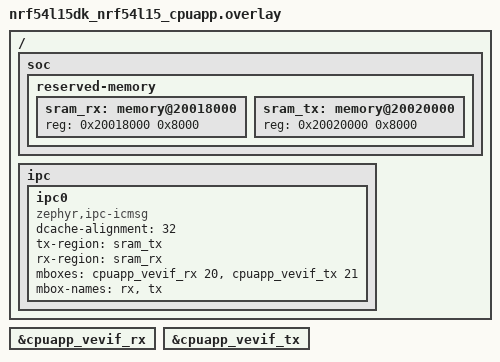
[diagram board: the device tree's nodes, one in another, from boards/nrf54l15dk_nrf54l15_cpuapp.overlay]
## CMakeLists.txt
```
#
# Copyright (c) 2024 Nordic Semiconductor ASA
#
# SPDX-License-Identifier: LicenseRef-Nordic-5-Clause
#

cmake_minimum_required(VERSION 3.20.0)

find_package(Zephyr REQUIRED HINTS $ENV{ZEPHYR_BASE})
project(ipc_service_host)

target_sources(app PRIVATE src/main.c)
```

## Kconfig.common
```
#
# Copyright (c) 2024 Nordic Semiconductor ASA
#
# SPDX-License-Identifier: LicenseRef-Nordic-5-Clause
#

config APP_IPC_SERVICE_SEND_INTERVAL
	int "Ipc service sending interval [us]"
	default 30 if BOARD_NRF5340DK_NRF5340_CPUNET
	default 70
	help
	  Time in micro seconds between sending subsequent data packages over
	  IPC service. Since kernel timeout has 1 ms resolution, the value is
	  rounded down. If value of this option is lower than 1000 us, busy
	  wait is used instead of sleep.

config APP_IPC_SERVICE_MESSAGE_LEN
	int "Length of single IPC message in bytes"
	default 100
```

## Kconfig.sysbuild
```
#
# Copyright (c) 2024 Nordic Semiconductor ASA
#
# SPDX-License-Identifier: LicenseRef-Nordic-5-Clause
#

source "share/sysbuild/Kconfig"

config REMOTE_BOARD
	string "The board used for remote target"
	default "nrf5340dk/nrf5340/cpunet" if BOARD_NRF5340DK_NRF5340_CPUAPP
	default "nrf5340dk/nrf5340/cpunet" if BOARD_NRF5340DK_NRF5340_CPUAPP_NS
	default "nrf54h20dk/nrf54h20/cpurad" if BOARD_NRF54H20DK_NRF54H20_CPUAPP
	default "nrf54l15dk/nrf54l15/cpuflpr" if BOARD_NRF54L15DK_NRF54L15_CPUAPP
	default "nrf54lm20pdk/nrf54lm20a/cpuflpr" if BOARD_NRF54LM20PDK_NRF54LM20A_CPUAPP
	default "nrf54lv10dk/nrf54lv10a/cpuflpr" if BOARD_NRF54LV10DK_NRF54LV10A_CPUAPP
```

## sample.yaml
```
sample:
  name: IPC Service integration test
  description: IPC Service integration and efficiency test

common:
  sysbuild: true
  tags:
    - ipc
    - ci_samples_ipc
  harness: console
  harness_config:
    type: multi_line
    ordered: true
    regex:
      - "IPC-service .* demo started"
      - "Δpkt: (?!0)\\d* ((?!0)\\d* B/pkt) | throughput: (?!0)\\d* bit/s"
      - "Δpkt: (?!0)\\d* ((?!0)\\d* B/pkt) | throughput: (?!0)\\d* bit/s"
      - "Δpkt: (?!0)\\d* ((?!0)\\d* B/pkt) | throughput: (?!0)\\d* bit/s"

tests:
  sample.ipc.ipc_service.nrf5340dk_rpmsg_default:
    platform_allow:
      - nrf5340dk/nrf5340/cpuapp
    integration_platforms:
      - nrf5340dk/nrf5340/cpuapp
  sample.ipc.ipc_service.nrf5340dk_rpmsg_cpuapp_sending:
    platform_allow:
      - nrf5340dk/nrf5340/cpuapp
    integration_platforms:
      - nrf5340dk/nrf5340/cpuapp
    extra_configs:
      - CONFIG_APP_IPC_SERVICE_SEND_INTERVAL=1
    extra_args:
      - remote_CONFIG_APP_IPC_SERVICE_SEND_INTERVAL=200000000
  sample.ipc.ipc_service.nrf5340dk_rpmsg_cpunet_sending:
    platform_allow:
      - nrf5340dk/nrf5340/cpuapp
    integration_platforms:
      - nrf5340dk/nrf5340/cpuapp
    extra_configs:
      - CONFIG_APP_IPC_SERVICE_SEND_INTERVAL=200000000
    extra_args:
      - remote_CONFIG_APP_IPC_SERVICE_SEND_INTERVAL=1
    harness_config:
      type: multi_line
      ordered: true
      regex:
        - "IPC-service .* demo started"
        # there will be only single tranfser from this core
        - "Δpkt: (?!0)\\d+ ((?!0)\\d+ B/pkt) | throughput: (?!0)\\d+ bit/s"
        - "Δpkt: \\d+ (\\d+ B/pkt) | throughput: \\d+ bit/s"
        - "Δpkt: \\d+ (\\d+ B/pkt) | throughput: \\d+ bit/s"
  sample.ipc.ipc_service.nrf5340dk_icmsg_default:
    platform_allow:
      - nrf5340dk/nrf5340/cpuapp
    integration_platforms:
      - nrf5340dk/nrf5340/cpuapp
    extra_args:
      - FILE_SUFFIX=icmsg
  sample.ipc.ipc_service.nrf5340dk_icbmsg_default:
    platform_allow:
      - nrf5340dk/nrf5340/cpuapp
    integration_platforms:
      - nrf5340dk/nrf5340/cpuapp
    extra_args:
      - FILE_SUFFIX=icbmsg
  sample.ipc.ipc_service.nrf5340dk_icmsg_cpuapp_sending:
    platform_allow:
      - nrf5340dk/nrf5340/cpuapp
    integration_platforms:
      - nrf5340dk/nrf5340/cpuapp
    extra_configs:
      - CONFIG_APP_IPC_SERVICE_SEND_INTERVAL=35
    extra_args:
      - FILE_SUFFIX=icmsg
      - remote_CONFIG_APP_IPC_SERVICE_SEND_INTERVAL=200000000
  sample.ipc.ipc_service.nrf5340dk_icmsg_cpunet_sending:
    platform_allow:
      - nrf5340dk/nrf5340/cpuapp
    integration_platforms:
      - nrf5340dk/nrf5340/cpuapp
    extra_configs:
      - CONFIG_APP_IPC_SERVICE_SEND_INTERVAL=200000000
    extra_args:
      - FILE_SUFFIX=icmsg
      - remote_CONFIG_APP_IPC_SERVICE_SEND_INTERVAL=1
    harness_config:
      type: multi_line
      ordered: true
      regex:
        - "IPC-service .* demo started"
        # there will be only single tranfser from this core
        - "Δpkt: (?!0)\\d+ ((?!0)\\d+ B/pkt) | throughput: (?!0)\\d+ bit/s"
        - "Δpkt: \\d+ (\\d+ B/pkt) | throughput: \\d+ bit/s"
        - "Δpkt: \\d+ (\\d+ B/pkt) | throughput: \\d+ bit/s"
  sample.ipc.ipc_service.nrf54h20dk_cpuapp_cpurad_icmsg:
    platform_allow:
      - nrf54h20dk/nrf54h20/cpuapp
    integration_platforms:
      - nrf54h20dk/nrf54h20/cpuapp
    extra_args:
      - ipc_service_CONFIG_SOC_NRF54H20_CPURAD_ENABLE=y
    timeout: 20
  sample.ipc.ipc_service.nrf54h20dk_cpuapp_cpuppr_icmsg:
    platform_allow:
      - nrf54h20dk/nrf54h20/cpuapp
    integration_platforms:
      - nrf54h20dk/nrf54h20/cpuapp
    extra_args:
      - FILE_SUFFIX=cpuppr
      - ipc_service_SNIPPET=nordic-ppr
    timeout: 20
  sample.ipc.ipc_service.nrf54l15dk_cpuapp_cpuflpr_icmsg:
    extra_args:
      - ipc_service_SNIPPET=nordic-flpr
    platform_allow:
      - nrf54l15dk/nrf54l15/cpuapp
    integration_platforms:
      - nrf54l15dk/nrf54l15/cpuapp
    timeout: 20
  sample.ipc.ipc_service.nrf54l15dk_cpuapp_cpuflpr_icbmsg:
    extra_args:
      - ipc_service_SNIPPET=nordic-flpr
      - ipc_service_CONFIG_IPC_SERVICE_BACKEND_ICBMSG_NUM_EP=1
      - ipc_service_DTC_OVERLAY_FILE="boards/nrf54l15dk_nrf54l15_cpuapp_icbmsg.overlay"
      - remote_CONFIG_IPC_SERVICE_BACKEND_ICBMSG_NUM_EP=1
      - remote_DTC_OVERLAY_FILE="boards/nrf54l15dk_nrf54l15_cpuflpr_icbmsg.overlay"
    platform_allow:
      - nrf54l15dk/nrf54l15/cpuapp
    integration_platforms:
      - nrf54l15dk/nrf54l15/cpuapp
    timeout: 20
  sample.ipc.ipc_service.nrf54lm20pdk_cpuapp_cpuflpr_icmsg:
    extra_args:
      - ipc_service_SNIPPET=nordic-flpr
    platform_allow:
      - nrf54lm20pdk/nrf54lm20a/cpuapp
      - nrf54lm20pdk@0.0.0/nrf54lm20a/cpuapp
      - nrf54lm20pdk@0.2.0/nrf54lm20a/cpuapp
      - nrf54lm20pdk@0.2.0.csp/nrf54lm20a/cpuapp
    integration_platforms:
      - nrf54lm20pdk/nrf54lm20a/cpuapp
    timeout: 20
  sample.ipc.ipc_service.nrf54lm20pdk_cpuapp_cpuflpr_icbmsg:
    extra_args:
      - ipc_service_SNIPPET=nordic-flpr
      - ipc_service_CONFIG_IPC_SERVICE_BACKEND_ICBMSG_NUM_EP=1
      - ipc_service_DTC_OVERLAY_FILE="boards/nrf54lm20pdk_nrf54lm20a_cpuapp_icbmsg.overlay"
      - remote_CONFIG_IPC_SERVICE_BACKEND_ICBMSG_NUM_EP=1
      - remote_DTC_OVERLAY_FILE="boards/nrf54lm20pdk_nrf54lm20a_cpuflpr_icbmsg.overlay"
    platform_allow:
      - nrf54lm20pdk/nrf54lm20a/cpuapp
      - nrf54lm20pdk@0.0.0/nrf54lm20a/cpuapp
      - nrf54lm20pdk@0.2.0/nrf54lm20a/cpuapp
      - nrf54lm20pdk@0.2.0.csp/nrf54lm20a/cpuapp
    integration_platforms:
      - nrf54lm20pdk/nrf54lm20a/cpuapp
    timeout: 20
  sample.ipc.ipc_service.nrf54lv10dk_cpuapp_cpuflpr_icmsg:
    extra_args:
      - ipc_service_SNIPPET=nordic-flpr
    platform_allow:
      - nrf54lv10dk/nrf54lv10a/cpuapp
      - nrf54lv10dk@0.0.0/nrf54lv10a/cpuapp
      - nrf54lv10dk@0.2.0/nrf54lv10a/cpuapp
    integration_platforms:
      - nrf54lv10dk/nrf54lv10a/cpuapp
    timeout: 20
  sample.ipc.ipc_service.nrf54lv10dk_cpuapp_cpuflpr_icbmsg:
    extra_args:
      - ipc_service_SNIPPET=nordic-flpr
      - ipc_service_CONFIG_IPC_SERVICE_BACKEND_ICBMSG_NUM_EP=1
      - ipc_service_DTC_OVERLAY_FILE="boards/nrf54lv10dk_nrf54lv10a_cpuapp_icbmsg.overlay"
      - remote_CONFIG_IPC_SERVICE_BACKEND_ICBMSG_NUM_EP=1
      - remote_DTC_OVERLAY_FILE="boards/nrf54lv10dk_nrf54lv10a_cpuflpr_icbmsg.overlay"
    platform_allow:
      - nrf54lv10dk/nrf54lv10a/cpuapp
      - nrf54lv10dk@0.0.0/nrf54lv10a/cpuapp
      - nrf54lv10dk@0.2.0/nrf54lv10a/cpuapp
    integration_platforms:
      - nrf54lv10dk/nrf54lv10a/cpuapp
    timeout: 20
```

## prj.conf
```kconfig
# Copyright (c) 2024 Nordic Semiconductor ASA
# SPDX-License-Identifier: LicenseRef-Nordic-5-Clause

CONFIG_PRINTK=y

CONFIG_LOG=y
CONFIG_LOG_PROCESS_THREAD_PRIORITY=-15
CONFIG_LOG_PROCESS_THREAD_CUSTOM_PRIORITY=y

CONFIG_HEAP_MEM_POOL_SIZE=4096

CONFIG_MBOX=y

CONFIG_IPC_SERVICE=y
CONFIG_IPC_SERVICE_LOG_LEVEL_INF=y
```

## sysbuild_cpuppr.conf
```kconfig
# Copyright (c) 2024 Nordic Semiconductor ASA
# SPDX-License-Identifier: LicenseRef-Nordic-5-Clause

SB_CONFIG_REMOTE_BOARD="nrf54h20dk/nrf54h20/cpuppr"
```

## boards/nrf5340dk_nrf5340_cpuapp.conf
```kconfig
#
# Copyright (c) 2022 Nordic Semiconductor ASA
#
# SPDX-License-Identifier: LicenseRef-Nordic-5-Clause
#

CONFIG_SOC_NRF53_CPUNET_ENABLE=y
CONFIG_OPENAMP=y
CONFIG_OPENAMP_SLAVE=n
```

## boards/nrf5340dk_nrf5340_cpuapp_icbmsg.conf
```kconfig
#
# Copyright (c) 2025 Nordic Semiconductor ASA
#
# SPDX-License-Identifier: LicenseRef-Nordic-5-Clause
#

CONFIG_SOC_NRF53_CPUNET_ENABLE=y
CONFIG_APP_IPC_SERVICE_SEND_INTERVAL=0
```

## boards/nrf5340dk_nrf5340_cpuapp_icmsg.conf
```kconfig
#
# Copyright (c) 2024 Nordic Semiconductor ASA
#
# SPDX-License-Identifier: LicenseRef-Nordic-5-Clause
#

CONFIG_SOC_NRF53_CPUNET_ENABLE=y
CONFIG_APP_IPC_SERVICE_SEND_INTERVAL=60
```

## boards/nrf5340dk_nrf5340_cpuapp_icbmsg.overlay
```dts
/*
 * Copyright (c) 2025 Nordic Semiconductor ASA
 *
 * SPDX-License-Identifier: LicenseRef-Nordic-5-Clause
 */

/delete-node/ &ipc0;

/ {
	chosen {
		/delete-property/ zephyr,ipc_shm;
		/delete-property/ zephyr,bt-hci;
	};

	reserved-memory {
		/delete-node/ memory@20070000;

		sram_tx: memory@20070000 {
			reg = <0x20070000 0x8000>;
		};

		sram_rx: memory@20078000 {
			reg = <0x20078000 0x8000>;
		};
	};

	ipc0: ipc0 {
		compatible = "zephyr,ipc-icbmsg";
		tx-region = <&sram_tx>;
		rx-region = <&sram_rx>;
		tx-blocks = <20>;
		rx-blocks = <20>;
		mboxes = <&mbox 0>, <&mbox 1>;
		mbox-names = "tx", "rx";
		status = "okay";
	};
};
```

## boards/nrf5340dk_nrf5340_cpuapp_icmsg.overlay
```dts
/*
* Copyright (c) 2022 Nordic Semiconductor ASA
*
* SPDX-License-Identifier: LicenseRef-Nordic-5-Clause
*/

/delete-node/ &ipc0;

/ {
	chosen {
		/delete-property/ zephyr,ipc_shm;
		/delete-property/ zephyr,bt-hci;
	};

	reserved-memory {
		/delete-node/ memory@20070000;

		sram_tx: memory@20070000 {
			reg = <0x20070000 0x8000>;
		};

		sram_rx: memory@20078000 {
			reg = <0x20078000 0x8000>;
		};
	};

	ipc0: ipc0 {
		compatible = "zephyr,ipc-icmsg";
		tx-region = <&sram_tx>;
		rx-region = <&sram_rx>;
		mboxes = <&mbox 0>, <&mbox 1>;
		mbox-names = "tx", "rx";
		status = "okay";
	};
};
```

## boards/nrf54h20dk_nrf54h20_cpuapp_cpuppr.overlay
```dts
/*
 * Copyright (c) 2024 Nordic Semiconductor ASA
 * SPDX-License-Identifier: LicenseRef-Nordic-5-Clause
 */

/* Replace default ipc0 instance */
/delete-node/ &ipc0;

ipc0: &cpuapp_cpuppr_ipc {
	status = "okay";
};

&cpuppr_vevif {
	status = "okay";
};

&cpuapp_bellboard {
	status = "okay";
};

/ {
	chosen {
		/delete-property/ zephyr,bt-hci;
	};
};
```

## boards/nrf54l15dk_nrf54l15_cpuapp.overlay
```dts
/*
 * Copyright (c) 2025 Nordic Semiconductor ASA
 *
 * SPDX-License-Identifier: LicenseRef-Nordic-5-Clause
 */

/ {
	soc {
		reserved-memory {
			#address-cells = <1>;
			#size-cells = <1>;

			sram_rx: memory@20018000 {
				reg = <0x20018000 0x8000>;
			};

			sram_tx: memory@20020000 {
				reg = <0x20020000 0x8000>;
			};
		};
	};

	ipc {
		ipc0: ipc0 {
			compatible = "zephyr,ipc-icmsg";
			dcache-alignment = <32>;
			tx-region = <&sram_tx>;
			rx-region = <&sram_rx>;
			mboxes = <&cpuapp_vevif_rx 20>, <&cpuapp_vevif_tx 21>;
			mbox-names = "rx", "tx";
			status = "okay";
		};
	};
};

&cpuapp_vevif_rx {
	status = "okay";
};

&cpuapp_vevif_tx {
	status = "okay";
};
```

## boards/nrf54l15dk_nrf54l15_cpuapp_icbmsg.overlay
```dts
/*
 * Copyright (c) 2025 Nordic Semiconductor ASA
 *
 * SPDX-License-Identifier: LicenseRef-Nordic-5-Clause
 */

/ {
	soc {
		reserved-memory {
			#address-cells = <1>;
			#size-cells = <1>;

			sram_rx: memory@20018000 {
				reg = <0x20018000 0x8000>;
			};

			sram_tx: memory@20020000 {
				reg = <0x20020000 0x8000>;
			};
		};
	};

	ipc {
		ipc0: ipc0 {
			compatible = "zephyr,ipc-icbmsg";
			dcache-alignment = <32>;
			tx-region = <&sram_tx>;
			rx-region = <&sram_rx>;
			tx-blocks = <16>;
			rx-blocks = <18>;
			mboxes = <&cpuapp_vevif_rx 20>, <&cpuapp_vevif_tx 21>;
			mbox-names = "rx", "tx";
			status = "okay";
		};
	};
};

&cpuapp_vevif_rx {
	status = "okay";
};

&cpuapp_vevif_tx {
	status = "okay";
};
```

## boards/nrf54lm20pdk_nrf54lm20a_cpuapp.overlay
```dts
/*
 * Copyright (c) 2025 Nordic Semiconductor ASA
 *
 * SPDX-License-Identifier: LicenseRef-Nordic-5-Clause
 */

/ {
	soc {
		reserved-memory {
			#address-cells = <1>;
			#size-cells = <1>;

			sram_rx: memory@20057c00 {
				reg = <0x20057c00 0x8000>;
			};

			sram_tx: memory@2005fc00 {
				reg = <0x2005fc00 0x8000>;
			};
		};
	};

	ipc {
		ipc0: ipc0 {
			compatible = "zephyr,ipc-icmsg";
			dcache-alignment = <32>;
			tx-region = <&sram_tx>;
			rx-region = <&sram_rx>;
			mboxes = <&cpuapp_vevif_rx 20>, <&cpuapp_vevif_tx 21>;
			mbox-names = "rx", "tx";
			status = "okay";
		};
	};
};

&cpuapp_vevif_rx {
	status = "okay";
};

&cpuapp_vevif_tx {
	status = "okay";
};
```

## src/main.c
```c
/*
 * Copyright (c) 2022 Nordic Semiconductor ASA
 *
 * SPDX-License-Identifier: LicenseRef-Nordic-5-Clause
 */

#include <zephyr/kernel.h>
#include <zephyr/device.h>
#include <string.h>

#include <zephyr/logging/log.h>

#include <zephyr/ipc/ipc_service.h>

#ifdef CONFIG_TEST_EXTRA_STACK_SIZE
#define STACKSIZE	(1024 + CONFIG_TEST_EXTRA_STACK_SIZE)
#else
#define STACKSIZE	(1024)
#endif

K_THREAD_STACK_DEFINE(ipc0_stack, STACKSIZE);

LOG_MODULE_REGISTER(host, LOG_LEVEL_INF);

struct payload {
	unsigned long cnt;
	unsigned long size;
	uint8_t data[];
};

struct payload *p_payload;

static K_SEM_DEFINE(bound_sem, 0, 1);

static void ep_bound(void *priv)
{
	k_sem_give(&bound_sem);
}

static void ep_recv(const void *data, size_t len, void *priv)
{
	uint8_t received_val = *((uint8_t *)data);
	static uint8_t expected_val;


	if ((received_val != expected_val) || (len != CONFIG_APP_IPC_SERVICE_MESSAGE_LEN)) {
		printk("Unexpected message received_val: %d , expected_val: %d\n",
			received_val,
			expected_val);
	}

	expected_val++;
}

static struct ipc_ept_cfg ep_cfg = {
	.name = "ep0",
	.cb = {
		.bound    = ep_bound,
		.received = ep_recv,
	},
};

static void check_task(void *arg1, void *arg2, void *arg3)
{
	ARG_UNUSED(arg1);
	ARG_UNUSED(arg2);
	ARG_UNUSED(arg3);

	unsigned long last_cnt = p_payload->cnt;
	unsigned long delta;

	while (1) {
		k_sleep(K_MSEC(1000));

		delta = p_payload->cnt - last_cnt;

		printk("Δpkt: %ld (%ld B/pkt) | throughput: %ld bit/s\n",
			delta, p_payload->size, delta * CONFIG_APP_IPC_SERVICE_MESSAGE_LEN * 8);

		last_cnt = p_payload->cnt;
	}
}

K_THREAD_DEFINE(thread_check_id, STACKSIZE, check_task, NULL, NULL, NULL,
		K_PRIO_COOP(1), 0, -1);

int main(void)
{
	const struct device *ipc0_instance;
	struct ipc_ept ep;
	int ret;

	p_payload = (struct payload *) k_malloc(CONFIG_APP_IPC_SERVICE_MESSAGE_LEN);
	if (!p_payload) {
		printk("k_malloc() failure\n");
		return -ENOMEM;
	}

	memset(p_payload->data, 0xA5, CONFIG_APP_IPC_SERVICE_MESSAGE_LEN - sizeof(struct payload));

	p_payload->size = CONFIG_APP_IPC_SERVICE_MESSAGE_LEN;
	p_payload->cnt = 0;

	printk("IPC-service %s demo started\n", CONFIG_BOARD_TARGET);

	ipc0_instance = DEVICE_DT_GET(DT_NODELABEL(ipc0));

#if defined(CONFIG_IPC_SERVICE_BACKEND_ICBMSG)
	/* Wait a bit for the remote core to boot. */
	k_msleep(100);
#endif

	ret = ipc_service_open_instance(ipc0_instance);
	if ((ret < 0) && (ret != -EALREADY)) {
		LOG_INF("ipc_service_open_instance() failure (%d)", ret);
		return ret;
	}

	ret = ipc_service_register_endpoint(ipc0_instance, &ep, &ep_cfg);
	if (ret < 0) {
		printf("ipc_service_register_endpoint() failure (%d)", ret);
		return ret;
	}

	k_sem_take(&bound_sem, K_FOREVER);
	k_thread_start(thread_check_id);

	while (true) {
		ret = ipc_service_send(&ep, p_payload, CONFIG_APP_IPC_SERVICE_MESSAGE_LEN);
		if (ret == -ENOMEM) {
			/* No space in the buffer. Retry. */
			continue;
		} else if (ret < 0) {
			printk("send_message(%ld) failed with ret %d\n", p_payload->cnt, ret);
			break;
		}

		p_payload->cnt++;


		/* Quasi minimal busy wait time which allows to continuously send
		 * data without -ENOMEM error code. The purpose is to test max
		 * throughput. Determined experimentally.
		 */
		if (CONFIG_APP_IPC_SERVICE_SEND_INTERVAL < 1000) {
			k_busy_wait(CONFIG_APP_IPC_SERVICE_SEND_INTERVAL);
		} else {
			k_msleep(CONFIG_APP_IPC_SERVICE_SEND_INTERVAL/1000);
		}
	}

	return 0;
}
```
